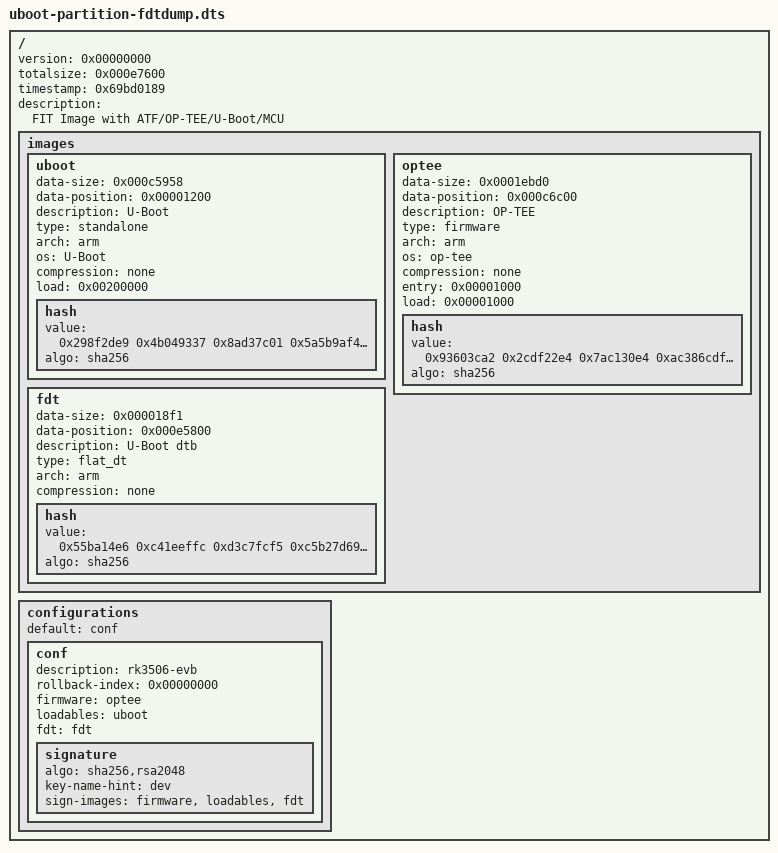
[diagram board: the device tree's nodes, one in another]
/dts-v1/;
// magic:		0xd00dfeed
// totalsize:		0x600 (1536)
// off_dt_struct:	0x48
// off_dt_strings:	0x4a0
// off_mem_rsvmap:	0x28
// version:		17
// last_comp_version:	16
// boot_cpuid_phys:	0x0
// size_dt_strings:	0xcb
// size_dt_struct:	0x458

/memreserve/ 0x7f2a1d5fe000 0x600;
/ {
    version = <0x00000000>;
    totalsize = <0x000e7600>;
    timestamp = <0x69bd0189>;
    description = "FIT Image with ATF/OP-TEE/U-Boot/MCU";
    #address-cells = <0x00000001>;
    images {
        uboot {
            data-size = <0x000c5958>;
            data-position = <0x00001200>;
            description = "U-Boot";
            type = "standalone";
            arch = "arm";
            os = "U-Boot";
            compression = "none";
            load = <0x00200000>;
            hash {
                value = <0x298f2de9 0x4b049337 0x8ad37c01 0x5a5b9af4 0xd1a99a12 0x27576704 0x5190932b 0x6a5aabff>;
                algo = "sha256";
            };
        };
        optee {
            data-size = <0x0001ebd0>;
            data-position = <0x000c6c00>;
            description = "OP-TEE";
            type = "firmware";
            arch = "arm";
            os = "op-tee";
            compression = "none";
            entry = <0x00001000>;
            load = <0x00001000>;
            hash {
                value = <0x93603ca2 0x2cdf22e4 0x7ac130e4 0xac386cdf 0x9474443a 0xb0760398 0x07dfc2d5 0xd30b7ecd>;
                algo = "sha256";
            };
        };
        fdt {
            data-size = <0x000018f1>;
            data-position = <0x000e5800>;
            description = "U-Boot dtb";
            type = "flat_dt";
            arch = "arm";
            compression = "none";
            hash {
                value = <0x55ba14e6 0xc41eeffc 0xd3c7fcf5 0xc5b27d69 0xc13a08e1 0x509e24d7 0x6fd71dd2 0xd415b14f>;
                algo = "sha256";
            };
        };
    };
    configurations {
        default = "conf";
        conf {
            description = "rk3506-evb";
            rollback-index = <0x00000000>;
            firmware = "optee";
            loadables = "uboot";
            fdt = "fdt";
            signature {
                algo = "sha256,rsa2048";
                key-name-hint = "dev";
                sign-images = "firmware", "loadables", "fdt";
            };
        };
    };
};
